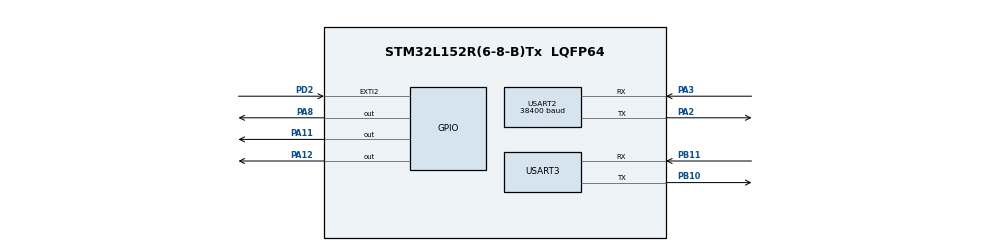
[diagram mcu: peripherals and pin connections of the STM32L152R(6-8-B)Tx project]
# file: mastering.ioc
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Dma.Request0=USART2_TX
Dma.USART2_TX.0.Direction=DMA_MEMORY_TO_PERIPH
Dma.USART2_TX.0.Instance=DMA1_Channel7
Dma.USART2_TX.0.MemDataAlignment=DMA_MDATAALIGN_BYTE
Dma.USART2_TX.0.MemInc=DMA_MINC_ENABLE
Dma.USART2_TX.0.Mode=DMA_NORMAL
Dma.USART2_TX.0.PeriphDataAlignment=DMA_PDATAALIGN_BYTE
Dma.USART2_TX.0.PeriphInc=DMA_PINC_DISABLE
Dma.USART2_TX.0.Priority=DMA_PRIORITY_LOW
Mcu.Family=STM32L1
Mcu.Name=STM32L152R(6-8-B)Tx
Mcu.Package=LQFP64
NVIC.DMA1_Channel7_IRQn=true\:5\:0\:true\:false\:true\:true\:true\:true
NVIC.EXTI2_IRQn=true\:0\:0\:true\:false\:true\:true\:true\:true
NVIC.PriorityGroup=NVIC_PRIORITYGROUP_4
NVIC.USART3_IRQn=true\:0\:0\:false\:false\:true\:true\:true\:true
PA11.GPIO_Speed=GPIO_SPEED_FREQ_LOW
PA11.Signal=GPIO_Output
PA12.GPIO_Speed=GPIO_SPEED_FREQ_LOW
PA12.Signal=GPIO_Output
PA13.Mode=Trace_Asynchronous_SW
PA13.Signal=SYS_JTMS-SWDIO
PA14.Mode=Trace_Asynchronous_SW
PA14.Signal=SYS_JTCK-SWCLK
PA2.Mode=Asynchronous
PA2.Signal=USART2_TX
PA3.Mode=Asynchronous
PA3.Signal=USART2_RX
PA8.GPIO_Speed=GPIO_SPEED_FREQ_LOW
PA8.Signal=GPIO_Output
PB10.Mode=Asynchronous
PB10.Signal=USART3_TX
PB11.Mode=Asynchronous
PB11.Signal=USART3_RX
PB3.Mode=Trace_Asynchronous_SW
PB3.Signal=SYS_JTDO-TRACESWO
PD2.GPIO_ModeDefaultEXTI=GPIO_MODE_IT_FALLING
PD2.GPIO_PuPd=GPIO_PULLUP
PD2.Signal=GPXTI2
ProjectManager.HeapSize=0x200
ProjectManager.StackSize=0x400
ProjectManager.TargetToolchain=CMake
RCC.48MHZClocksFreq_Value=32000000
RCC.AHBFreq_Value=32000000
RCC.APB1Freq_Value=32000000
RCC.APB1TimFreq_Value=32000000
RCC.APB2Freq_Value=32000000
RCC.APB2TimFreq_Value=32000000
RCC.HCLKFreq_Value=32000000
RCC.HSE_VALUE=24000000
RCC.HSI_VALUE=16000000
RCC.LSE_VALUE=32768
RCC.MSI_VALUE=2097000
RCC.PLLMUL=RCC_PLL_MUL4
RCC.SYSCLKFreq_VALUE=32000000
RCC.SYSCLKSource=RCC_SYSCLKSOURCE_PLLCLK
RCC.VCOOutputFreq_Value=64000000
USART2.BaudRate=38400
USART2.VirtualMode=VM_ASYNC
USART3.VirtualMode=VM_ASYNC
VP_SYS_V_PVD_IN.Mode=Mode_PVD_Int
board=custom

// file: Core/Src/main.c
/* USER CODE BEGIN Header */
/**
  ******************************************************************************
  * @file           : main.c
  * @brief          : Main program body
  ******************************************************************************
  * @attention
  *
  * Copyright (c) 2024 STMicroelectronics.
  * All rights reserved.
  *
  * This software is licensed under terms that can be found in the LICENSE file
  * in the root directory of this software component.
  * If no LICENSE file comes with this software, it is provided AS-IS.
  *
  ******************************************************************************
  */
/* USER CODE END Header */
#include "main.h"
#include "dma.h"
#include "usart.h"
#include "gpio.h"

/* USER CODE BEGIN Includes */
#include <stdio.h>
#include "app.hpp"
/* USER CODE END Includes */

void SystemClock_Config(void);

int main(void)
{

  /* MCU Configuration--------------------------------------------------------*/

  /* Reset of all peripherals, Initializes the Flash interface and the Systick. */
  HAL_Init();

  /* Configure the system clock */
  SystemClock_Config();

  /* Initialize all configured peripherals */
  MX_GPIO_Init();
  MX_DMA_Init();
  MX_USART2_UART_Init();
  MX_USART3_UART_Init();

  /* Infinite loop */
  /* USER CODE BEGIN WHILE */
  app_c();
    /* USER CODE END WHILE */

}

void SystemClock_Config(void)
{

  LL_FLASH_Enable64bitAccess();

  LL_FLASH_SetLatency(LL_FLASH_LATENCY_1);
  while(LL_FLASH_GetLatency()!= LL_FLASH_LATENCY_1)
  {
  }
  LL_PWR_SetRegulVoltageScaling(LL_PWR_REGU_VOLTAGE_SCALE1);
  while (LL_PWR_IsActiveFlag_VOS() != 0)
  {
  }
  LL_RCC_HSI_Enable();

   /* Wait till HSI is ready */
  while(LL_RCC_HSI_IsReady() != 1)
  {

  }
  LL_RCC_HSI_SetCalibTrimming(16);
  LL_RCC_PLL_ConfigDomain_SYS(LL_RCC_PLLSOURCE_HSI, LL_RCC_PLL_MUL_4, LL_RCC_PLL_DIV_2);
  LL_RCC_PLL_Enable();

   /* Wait till PLL is ready */
  while(LL_RCC_PLL_IsReady() != 1)
  {

  }
  LL_RCC_SetAHBPrescaler(LL_RCC_SYSCLK_DIV_1);
  LL_RCC_SetAPB1Prescaler(LL_RCC_APB1_DIV_1);
  LL_RCC_SetAPB2Prescaler(LL_RCC_APB2_DIV_1);
  LL_RCC_SetSysClkSource(LL_RCC_SYS_CLKSOURCE_PLL);

   /* Wait till System clock is ready */
  while(LL_RCC_GetSysClkSource() != LL_RCC_SYS_CLKSOURCE_STATUS_PLL)
  {

  }
  LL_SetSystemCoreClock(32000000);

   /* Update the time base */
  if (HAL_InitTick (TICK_INT_PRIORITY) != HAL_OK)
  {
    Error_Handler();
  }
}

void Error_Handler(void)
{
    __disable_irq();
    while (1) {
    }
}
